AUTOSAR XML (schema 4-2-2)
package /STELLANTIS/EPT/ASWCs
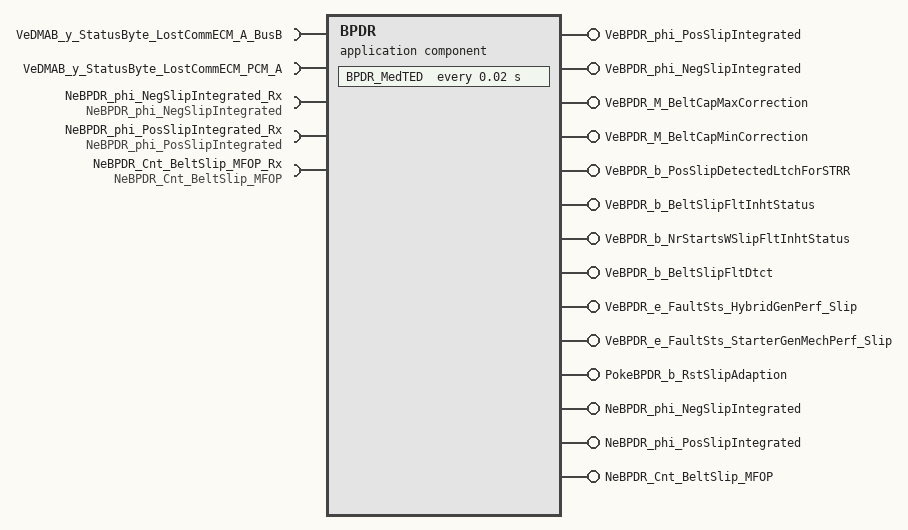
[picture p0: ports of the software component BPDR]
  application sw component type BPDR
    require port VeDMAB_y_StatusByte_LostCommECM_A_BusB: nonqueued-receiver-com-spec{data-element=Value, init-value=0}, required-interface=VeDMAB_y_StatusByte_LostCommECM_A_BusB
    require port VeDMAB_y_StatusByte_LostCommECM_PCM_A: nonqueued-receiver-com-spec{data-element=Value, init-value=0}, required-interface=VeDMAB_y_StatusByte_LostCommECM_PCM_A
    11 x provide port:
      VeBPDR_phi_PosSlipIntegrated: nonqueued-sender-com-spec{data-element=Value, init-value=0}, provided-interface=VeBPDR_phi_PosSlipIntegrated
      VeBPDR_phi_NegSlipIntegrated: nonqueued-sender-com-spec{data-element=Value, init-value=0}, provided-interface=VeBPDR_phi_NegSlipIntegrated
      VeBPDR_M_BeltCapMaxCorrection: nonqueued-sender-com-spec{data-element=Value, init-value=0}, provided-interface=VeBPDR_M_BeltCapMaxCorrection
      VeBPDR_M_BeltCapMinCorrection: nonqueued-sender-com-spec{data-element=Value, init-value=0}, provided-interface=VeBPDR_M_BeltCapMinCorrection
      VeBPDR_b_PosSlipDetectedLtchForSTRR: nonqueued-sender-com-spec{data-element=Value, init-value=0}, provided-interface=VeBPDR_b_PosSlipDetectedLtchForSTRR
      VeBPDR_b_BeltSlipFltInhtStatus: nonqueued-sender-com-spec{data-element=Value, init-value=0}, provided-interface=VeBPDR_b_BeltSlipFltInhtStatus
      VeBPDR_b_NrStartsWSlipFltInhtStatus: nonqueued-sender-com-spec{data-element=Value, init-value=0}, provided-interface=VeBPDR_b_NrStartsWSlipFltInhtStatus
      VeBPDR_b_BeltSlipFltDtct: nonqueued-sender-com-spec{data-element=Value, init-value=0}, provided-interface=VeBPDR_b_BeltSlipFltDtct
      VeBPDR_e_FaultSts_HybridGenPerf_Slip: nonqueued-sender-com-spec{data-element=Value, init-value=CeDFIB_e_Init}, provided-interface=VeBPDR_e_FaultSts_HybridGenPerf_Slip
      VeBPDR_e_FaultSts_StarterGenMechPerf_Slip: nonqueued-sender-com-spec{data-element=Value, init-value=CeDFIB_e_Init}, provided-interface=VeBPDR_e_FaultSts_StarterGenMechPerf_Slip
      PokeBPDR_b_RstSlipAdaption: server-com-spec=PokeBPDR_b_RstSlipAdaption, provided-interface=PokeBPDR_b_RstSlipAdaption
    require port NeBPDR_phi_NegSlipIntegrated_Rx: nv-require-com-spec{init-value=0, variable=NeBPDR_phi_NegSlipIntegrated}, required-interface=NeBPDR_phi_NegSlipIntegrated
    require port NeBPDR_phi_PosSlipIntegrated_Rx: nv-require-com-spec{init-value=0, variable=NeBPDR_phi_PosSlipIntegrated}, required-interface=NeBPDR_phi_PosSlipIntegrated
    require port NeBPDR_Cnt_BeltSlip_MFOP_Rx: nv-require-com-spec{init-value=0, variable=NeBPDR_Cnt_BeltSlip_MFOP}, required-interface=NeBPDR_Cnt_BeltSlip_MFOP
    provide port NeBPDR_phi_NegSlipIntegrated: nv-provide-com-spec{ram-block-init-value=0, variable=NeBPDR_phi_NegSlipIntegrated}, provided-interface=NeBPDR_phi_NegSlipIntegrated
    provide port NeBPDR_phi_PosSlipIntegrated: nv-provide-com-spec{ram-block-init-value=0, variable=NeBPDR_phi_PosSlipIntegrated}, provided-interface=NeBPDR_phi_PosSlipIntegrated
    provide port NeBPDR_Cnt_BeltSlip_MFOP: nv-provide-com-spec{ram-block-init-value=0, variable=NeBPDR_Cnt_BeltSlip_MFOP}, provided-interface=NeBPDR_Cnt_BeltSlip_MFOP
    behavior IB_BPDR: data-type-mapping=msADTtoIDTMapping, handle-termination-and-restart=NO-SUPPORT
      timing event Event_MedTED: start-on-event=BPDR_MedTED, period=0.02
      operation invoked event Event_PokeBPDR_b_RstSlipAdaption: start-on-event=PokeBPDR_b_RstSlipAdaption, operation=PokeBPDR_b_RstSlipAdaption.PokeBPDR_b_RstSlipAdaption
      init event Event_BPDR_ac_Init: start-on-event=BPDR_ac_Init
      init event Event_PwrOn: start-on-event=BPDR_PwrOn
      init event Event_PwrOff: start-on-event=BPDR_PwrOff
      5 x runnable:
        BPDR_ac_Init
          data-send-points:
            access OUT_VeBPDR_e_FaultSts_HybridGenPerf_Slip_Value: accessed-variable=VeBPDR_e_FaultSts_HybridGenPerf_Slip.Value
            access OUT_VeBPDR_e_FaultSts_StarterGenMechPerf_Slip_Value: accessed-variable=VeBPDR_e_FaultSts_StarterGenMechPerf_Slip.Value
        BPDR_MedTED
          data-receive-point-by-arguments:
            access IN_VeDMAB_y_StatusByte_LostCommECM_A_BusB_Value: accessed-variable=VeDMAB_y_StatusByte_LostCommECM_A_BusB.Value
            access IN_VeDMAB_y_StatusByte_LostCommECM_PCM_A_Value: accessed-variable=VeDMAB_y_StatusByte_LostCommECM_PCM_A.Value
          data-send-points:
            10 x access:
              OUT_VeBPDR_phi_PosSlipIntegrated_Value: accessed-variable=VeBPDR_phi_PosSlipIntegrated.Value
              OUT_VeBPDR_phi_NegSlipIntegrated_Value: accessed-variable=VeBPDR_phi_NegSlipIntegrated.Value
              OUT_VeBPDR_M_BeltCapMaxCorrection_Value: accessed-variable=VeBPDR_M_BeltCapMaxCorrection.Value
              OUT_VeBPDR_M_BeltCapMinCorrection_Value: accessed-variable=VeBPDR_M_BeltCapMinCorrection.Value
              OUT_VeBPDR_b_PosSlipDetectedLtchForSTRR_Value: accessed-variable=VeBPDR_b_PosSlipDetectedLtchForSTRR.Value
              OUT_VeBPDR_b_BeltSlipFltInhtStatus_Value: accessed-variable=VeBPDR_b_BeltSlipFltInhtStatus.Value
              OUT_VeBPDR_b_NrStartsWSlipFltInhtStatus_Value: accessed-variable=VeBPDR_b_NrStartsWSlipFltInhtStatus.Value
              OUT_VeBPDR_b_BeltSlipFltDtct_Value: accessed-variable=VeBPDR_b_BeltSlipFltDtct.Value
              OUT_VeBPDR_e_FaultSts_HybridGenPerf_Slip_Value: accessed-variable=VeBPDR_e_FaultSts_HybridGenPerf_Slip.Value
              OUT_VeBPDR_e_FaultSts_StarterGenMechPerf_Slip_Value: accessed-variable=VeBPDR_e_FaultSts_StarterGenMechPerf_Slip.Value
        BPDR_PwrOn
          data-receive-point-by-arguments:
            access IN_NeBPDR_Cnt_BeltSlip_MFOP_Rx_NeBPDR_Cnt_BeltSlip_MFOP: accessed-variable=NeBPDR_Cnt_BeltSlip_MFOP_Rx.NeBPDR_Cnt_BeltSlip_MFOP
            access IN_NeBPDR_phi_NegSlipIntegrated_Rx_NeBPDR_phi_NegSlipIntegrated: accessed-variable=NeBPDR_phi_NegSlipIntegrated_Rx.NeBPDR_phi_NegSlipIntegrated
            access IN_NeBPDR_phi_PosSlipIntegrated_Rx_NeBPDR_phi_PosSlipIntegrated: accessed-variable=NeBPDR_phi_PosSlipIntegrated_Rx.NeBPDR_phi_PosSlipIntegrated
          data-send-points:
            10 x access:
              OUT_VeBPDR_phi_PosSlipIntegrated_Value: accessed-variable=VeBPDR_phi_PosSlipIntegrated.Value
              OUT_VeBPDR_phi_NegSlipIntegrated_Value: accessed-variable=VeBPDR_phi_NegSlipIntegrated.Value
              OUT_VeBPDR_M_BeltCapMaxCorrection_Value: accessed-variable=VeBPDR_M_BeltCapMaxCorrection.Value
              OUT_VeBPDR_M_BeltCapMinCorrection_Value: accessed-variable=VeBPDR_M_BeltCapMinCorrection.Value
              OUT_VeBPDR_b_PosSlipDetectedLtchForSTRR_Value: accessed-variable=VeBPDR_b_PosSlipDetectedLtchForSTRR.Value
              OUT_VeBPDR_b_BeltSlipFltInhtStatus_Value: accessed-variable=VeBPDR_b_BeltSlipFltInhtStatus.Value
              OUT_VeBPDR_b_NrStartsWSlipFltInhtStatus_Value: accessed-variable=VeBPDR_b_NrStartsWSlipFltInhtStatus.Value
              OUT_VeBPDR_b_BeltSlipFltDtct_Value: accessed-variable=VeBPDR_b_BeltSlipFltDtct.Value
              OUT_VeBPDR_e_FaultSts_HybridGenPerf_Slip_Value: accessed-variable=VeBPDR_e_FaultSts_HybridGenPerf_Slip.Value
              OUT_VeBPDR_e_FaultSts_StarterGenMechPerf_Slip_Value: accessed-variable=VeBPDR_e_FaultSts_StarterGenMechPerf_Slip.Value
        BPDR_PwrOff
          data-send-points:
            access OUT_NeBPDR_phi_NegSlipIntegrated_NeBPDR_phi_NegSlipIntegrated: accessed-variable=NeBPDR_phi_NegSlipIntegrated.NeBPDR_phi_NegSlipIntegrated
            access OUT_NeBPDR_phi_PosSlipIntegrated_NeBPDR_phi_PosSlipIntegrated: accessed-variable=NeBPDR_phi_PosSlipIntegrated.NeBPDR_phi_PosSlipIntegrated
            access OUT_NeBPDR_Cnt_BeltSlip_MFOP_NeBPDR_Cnt_BeltSlip_MFOP: accessed-variable=NeBPDR_Cnt_BeltSlip_MFOP.NeBPDR_Cnt_BeltSlip_MFOP
        PokeBPDR_b_RstSlipAdaption
      variation point proxy Variant_BPDR_1: category=CONDITION, condition-access=0
